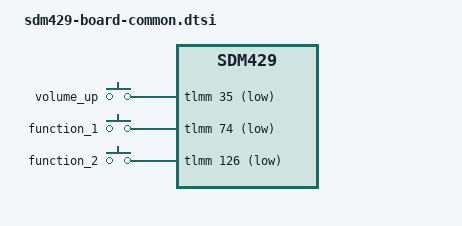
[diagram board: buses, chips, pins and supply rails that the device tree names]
/* Copyright (c) 2020, The Linux Foundation. All rights reserved.
 *
 * This program is free software; you can redistribute it and/or modify
 * it under the terms of the GNU General Public License version 2 and
 * only version 2 as published by the Free Software Foundation.
 *
 * This program is distributed in the hope that it will be useful,
 * but WITHOUT ANY WARRANTY; without even the implied warranty of
 * MERCHANTABILITY or FITNESS FOR A PARTICULAR PURPOSE.  See the
 * GNU General Public License for more details.
 */

&soc {
	gpio_keys: gpio_keys {
		compatible = "gpio-keys";
		label = "gpio-keys";
		pinctrl-names = "default";
		pinctrl-0 = <&gpio_key_active>;
		pinctrl-1 = <&gpio_key_suspend>;

		vol_up: vol_up {
			label = "volume_up";
			gpios = <&tlmm 35 0x1>;
			linux,input-type = <1>;
			linux,code = <115>;
			debounce-interval = <15>;
			linux,can-disable;
			gpio-key,wakeup;
		};

		function_1: function_1 {
			label = "function_1";
			gpios = <&tlmm 74 0x1>;
			linux,input-type = <1>;
			linux,code = <116>;
			debounce-interval = <15>;
			linux,can-disable;
			gpio-key,wakeup;
		};

		function_2: function_2 {
			label = "function_2";
			gpios = <&tlmm 126 0x1>;
			linux,input-type = <1>;
			linux,code = <117>;
			debounce-interval = <15>;
			linux,can-disable;
			gpio-key,wakeup;
		};
	};
};
